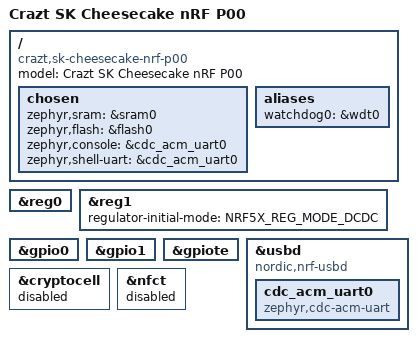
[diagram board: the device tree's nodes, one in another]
// Copyright (c) 2026
// SPDX-License-Identifier: Apache-2.0

#include <nordic/nrf52840_qiaa.dtsi>

/ {
	model = "Crazt SK Cheesecake nRF P00";
	compatible = "crazt,sk-cheesecake-nrf-p00";

	chosen {
		zephyr,sram = &sram0;
		zephyr,flash = &flash0;
		zephyr,console = &cdc_acm_uart0;
		zephyr,shell-uart = &cdc_acm_uart0;
	};

	aliases {
		watchdog0 = &wdt0;
	};
};

&reg0 {
	status = "okay";
};

&reg1 {
	regulator-initial-mode = <NRF5X_REG_MODE_DCDC>;
};

&gpio0 {
	status = "okay";
};

&gpio1 {
	status = "okay";
};

&gpiote {
	status = "okay";
};

zephyr_udc0: &usbd {
	compatible = "nordic,nrf-usbd";
	status = "okay";
	cdc_acm_uart0: cdc_acm_uart0 {
		compatible = "zephyr,cdc-acm-uart";
	};
};

&cryptocell {
	status = "disabled";
};

&nfct {
	status = "disabled";
};
